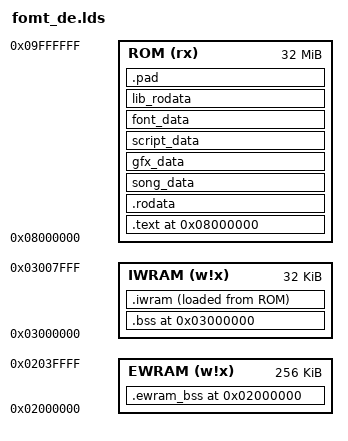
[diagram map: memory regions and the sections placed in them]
OUTPUT_ARCH(arm)
ENTRY(_start)

_M4aMaxLines = 0x50;

MEMORY
{
    EWRAM (w!x) : ORIGIN = 0x02000000, LENGTH = 256K
    IWRAM (w!x) : ORIGIN = 0x03000000, LENGTH = 32K
    ROM   (rx)  : ORIGIN = 0x08000000, LENGTH = 32M
}

SECTIONS
{
    .ewram_bss 0x02000000 (NOLOAD) :
    ALIGN(4)
    {
        src/m4a.o(ewram_data);
        __ewram_bss_end = .;
    } > EWRAM

    .bss 0x03000000 (NOLOAD) :
    ALIGN(4)
    {
        src/m4a.o(.bss);
        src/sram_access.o(.bss);
        src/obj_palette_pool.o(.bss COMMON);
        src/obj_tile_pool.o(.bss COMMON);
        src/game_scene_controller.o(.bss COMMON);
        src/hardware_vblank_binding.o(.bss COMMON);
        src/ui_vcount.o(.bss COMMON);
        src/heap.o(.bss COMMON);
        src/joy_bus.o(.bss);
        src/interrupt_table.o(.bss COMMON);
    } > IWRAM

    . = 0x08000000;

    .text :
    ALIGN(4)
    {
        asm/crt0.o(.text);
        src/main.o(.text);
        src/sram_image.o(.text);
        src/interrupt.o(.text);
        src/new.o(.text);
        src/pure_virtual.o(.text);
        src/sram_access.o(.text);
        src/scene.o(.text);
        src/intro_scene.o(.text);
        src/new_game_menu.o(.text);
        src/new_game_name_entry.o(.text);
        src/new_game_identity.o(.text);
        src/new_game_name_input.o(.text);
        src/obj_palette_pool.o(.text);
        src/obj_palette_collection.o(.text);
        src/obj_tile_bitmap.o(.text);
        src/obj_tile_pool.o(.text);
        src/obj_tile_collection.o(.text);
        src/hardware_context.o(.text);
        src/hardware_manager.o(.text);
        src/hardware_sound.o(.text);
        src/hardware_dma.o(.text);
        src/hardware_input.o(.text);
        src/hardware_blend.o(.text);
        src/hardware_blend_tables.o(.text);
        src/hardware_interrupt_guard.o(.text);
        src/hardware_display_state.o(.text);
        src/hardware_sprite_buffer.o(.text);
        src/hardware_linked_list.o(.text);
        src/farm.o(.text);
        src/field.o(.text);
        src/shipping_bin.o(.text);
        src/tool_chest.o(.text);
        src/fridge.o(.text);
        src/shelf.o(.text);
        src/record_player.o(.text);
        src/furniture.o(.text);
        src/farm_house.o(.text);
        src/coop.o(.text);
        src/barn.o(.text);
        src/item.o(.text);
        src/calendar.o(.text);
        src/farmer.o(.text);
        src/rucksack_item.o(.text);
        src/held_item.o(.text);
        src/rucksack.o(.text);
        src/more_items.o(.text);
        src/game_scene_controller.o(.text);
        src/game_state.o(.text);
        src/game_scene.o(.text);
        src/farm_terrain.o(.text);
        src/game_world.o(.text);
        src/game_world_interface.o(.text);
        src/entity.o(.text);
        src/animal_response.o(.text);
        src/animal_actor.o(.text);
        src/player_actor.o(.text);
        src/entity_actor.o(.text);
        src/harvest_sprite_actor.o(.text);
        src/npc_entity.o(.text);
        src/roaming_npc_actor.o(.text);
        src/world_prop_entities.o(.text);
        src/wild_dog_actor.o(.text);
        src/world_ambient_sprites.o(.text);
        src/world_ambient_entity_factory.o(.text);
        src/world_ambient_animation.o(.text);
        src/map_selection.o(.text);
        src/entity_auxiliary_sprites.o(.text);
        src/world_weather.o(.text);
        src/scene_text_variables.o(.text);
        src/farming_tutorial_transition.o(.text);
        src/ui_text_window.o(.text);
        src/main_menu_widget.o(.text);
        src/map_clock_status.o(.text);
        src/npc_schedule.o(.text);
        src/npc_schedule_rick.o(.text);
        src/npc_schedule_popuri.o(.text);
        src/npc_schedule_lillia.o(.text);
        src/npc_schedule_child.o(.text);
        src/npc_schedule_cliff.o(.text);
        src/npc_schedule_zack.o(.text);
        src/npc_schedule_doctor.o(.text);
        src/npc_schedule_ellen.o(.text);
        src/npc_schedule_jeff.o(.text);
        src/npc_schedule_karen.o(.text);
        src/npc_schedule_sasha.o(.text);
        src/npc_schedule_doug.o(.text);
        src/npc_schedule_ann.o(.text);
        src/npc_schedule_lou.o(.text);
        src/npc_schedule_basil.o(.text);
        src/npc_schedule_mary.o(.text);
        src/npc_schedule_anna.o(.text);
        src/npc_schedule_won.o(.text);
        src/npc_schedule_thomas.o(.text);
        src/npc_schedule_elli.o(.text);
        src/npc_schedule_stu.o(.text);
        src/npc_schedule_duke.o(.text);
        src/npc_schedule_manna.o(.text);
        src/npc_schedule_van.o(.text);
        src/npc_schedule_harris.o(.text);
        src/npc_schedule_carter.o(.text);
        src/npc_schedule_kai.o(.text);
        src/npc_schedule_gray.o(.text);
        src/npc_schedule_saibara.o(.text);
        src/npc_schedule_gotz.o(.text);
        src/npc_schedule_may.o(.text);
        src/npc_schedule_barley.o(.text);
        src/script_vm.o(.text);
        src/script_engine.o(.text);
        src/font_draw.o(.text);
        src/sprite_oam.o(.text);
        src/decimal_text.o(.text);
        src/font_decimal.o(.text);
        src/ui_text_rows.o(.text);
        src/ui_state.o(.text);
        src/ui_text_window_border.o(.text);
        src/frisbee_scoreboard.o(.text);
        src/animal_festival_ranking.o(.text);
        src/frisbee_core.o(.text);
        src/frisbee.o(.text);
        src/horse_race.o(.text);
        src/horse_race_medal_exchange.o(.text);
        src/resource_archive.o(.text);
        src/resource_handle.o(.text);
        src/intro_story_scene.o(.text);
        src/farm_status_screen.o(.text);
        src/animal_festival_selection.o(.text);
        src/new_game_birthday_input.o(.text);
        src/farm_map_screen.o(.text);
        src/records_screen.o(.text);
        src/resource_sprite_renderer.o(.text);
        src/scroll_state.o(.text);
        src/scroll_menu.o(.text);
        src/staff_credits.o(.text);
        src/town_map.o(.text);
        src/scene_reference_page.o(.text);
        src/scene_poultry_farm_shop.o(.text);
        src/scene_supermarket.o(.text);
        src/scene_clinic_shop.o(.text);
        src/scene_inn_shop.o(.text);
        src/scene_won_shop.o(.text);
        src/scene_winery_shop.o(.text);
        src/scene_special_merchant_shop.o(.text);
        src/scene_beach_cafe_shop.o(.text);
        src/scene_blacksmith_shop.o(.text);
        src/scene_carpenter_shop.o(.text);
        src/scene_yodel_ranch_shop.o(.text);
        src/scene_refrigerator.o(.text);
        src/scene_rucksack.o(.text);
        src/scene_shelf.o(.text);
        src/scene_tool_chest.o(.text);
        src/scene_blacksmith_upgrade.o(.text);
        src/scene_gift_wrapping.o(.text);
        src/scene_gamecube_link.o(.text);
        src/gamecube_link_save.o(.text);
        src/world_sprite_buffer.o(.text);
        src/scene_cooking.o(.text);
        src/cooking_recipe.o(.text);
        src/cooking_recipe_inventory.o(.text);
        src/money_account.o(.text);
        src/actor.o(.text);
        src/animal.o(.text);
        src/pet.o(.text);
        src/livestock.o(.text);
        src/barn_animal.o(.text);
        src/dog.o(.text);
        src/horse.o(.text);
        src/chicken.o(.text);
        src/cow.o(.text);
        src/sheep.o(.text);
        src/actor_runtime_data.o(.text);
        src/cursed_tool.o(.text);
        src/map_patch_flags.o(.text);
        src/event_state.o(.text);
        src/fishing_results_data.o(.text);
        src/mine_floor.o(.text);
        src/npc.o(.text);
        src/bachelorette.o(.text);
        src/harvest_sprite.o(.text);
        src/child.o(.text);
        src/gotz.o(.text);
        src/saibara.o(.text);
        src/van.o(.text);
        src/npc_collection.o(.text);
        src/npc_locations.o(.text);
        src/field_item_data.o(.text);
        src/scene_calendar_core.o(.text);
        src/scene_calendar.o(.text);
        src/scene_minigames.o(.text);
        src/name_entry.o(.text);
        src/fishing.o(.text);
        src/fishing_area.o(.text);
        src/time_of_day.o(.text);
        src/map_data.o(.text);
        src/scene_sprite.o(.text);
        src/world_map.o(.text);
        src/world_saved_map.o(.text);
        src/saved_map_graphics.o(.text);
        src/world_sprite_effects.o(.text);
        src/random.o(.text);
        src/actor_movement.o(.text);
        src/map_terrain.o(.text);
        src/world_runtime.o(.text);
        src/farming_tutorial_world.o(.text);
        src/wedding_date.o(.text);
        src/ui_portrait.o(.text);
        src/ui_text_stream.o(.text);
        src/scene_animal_care_minigame.o(.text);
        src/scene_chicken_festival.o(.text);
        src/scene_harvesting_minigame.o(.text);
        src/scene_watering_minigame.o(.text);
        src/shop_common.o(.text);
        src/ui_quantity_selector.o(.text);
        src/shop_ui.o(.text);
        src/game_menu_panels.o(.text);
        src/game_menu.o(.text);
        src/farming_tutorial_map.o(.text);
        src/heap.o(.text);
        src/joy_bus.o(.text);
        src/link_communication_value.o(.text);
        src/font.o(.text);
        asm/hardware_dma.o(.text);
        asm/integer_division.o(.text);
        src/interrupt_table.o(.text);
        asm/compression.o(.text);
        src/libc_random.o(.text);
        asm/compression_packets.o(.text);
        asm/m4a_1.o(.text);
        src/m4a.o(.text);
        asm/gbasvc.o(.text);
        src/libsram.o(.text);
        *libgcc.a:_call_via_rX.o(.text);
        src/libc_string.o(.text);
        src/allocation_failure.o(.text);
        src/intro_scene_factory.o(.text);
        src/intro_scene_lifetimes.o(.text);
        src/resource_archive_provider.o(.text);
        src/new_game_menu_factory.o(.text);
        src/new_game_menu_lifetimes.o(.text);
        src/game_scene_records.o(.text);
        src/game_state_copy.o(.text);
        src/new_game_name_entry_factory.o(.text);
        src/new_game_name_entry_lifetimes.o(.text);
        src/obj_palette_pool_storage.o(.text);
        src/obj_palette_collection_storage.o(.text);
        src/obj_tile_pool_storage.o(.text);
        src/obj_tile_collection_storage.o(.text);
        src/hardware_context_commands.o(.text);
        src/hardware_vblank_binding.o(.text);
        src/hardware_manager_tables.o(.text);
        src/hardware_vblank_list.o(.text);
        src/hardware_manager_lifetimes.o(.text);
        src/hardware_sound_command_lifetimes.o(.text);
        src/hardware_linked_list_lifetimes.o(.text);
        src/livestock_copy.o(.text);
        src/rucksack_slots.o(.text);
        src/game_scene_script_queue.o(.text);
        src/npc_schedule_search.o(.text);
        src/game_scene_state.o(.text);
        src/town_map_transition.o(.text);
        src/town_map_transition_lifetimes.o(.text);
        src/scene_menu_transitions.o(.text);
        src/town_map_selection.o(.text);
        src/scene_clock_transition.o(.text);
        src/scene_clock_transition_lifetimes.o(.text);
        src/game_scene_return.o(.text);
        src/game_scene_return_lifetimes.o(.text);
        src/game_scene_actions.o(.text);
        src/gamecube_link_scene.o(.text);
        src/gamecube_link_scene_lifetimes.o(.text);
        src/status_screen_transitions.o(.text);
        src/saved_map_tree_erase.o(.text);
        src/scene_sprite_group.o(.text);
        src/game_object.o(.text);
        src/animal_actor_lifetimes.o(.text);
        src/player_actor_search.o(.text);
        src/farming_tutorial_player_lifetimes.o(.text);
        src/player_actor_lifetimes.o(.text);
        src/scene_sprite_indexed.o(.text);
        src/scene_sprite_copy.o(.text);
        src/entity_actor_lifetimes.o(.text);
        src/harvest_sprite_actor_lifetimes.o(.text);
        src/npc_path_search.o(.text);
        src/npc_actor_lifetimes.o(.text);
        src/world_prop_lifetimes.o(.text);
        src/world_ambient_behaviors.o(.text);
        src/scene_text_variable_lifetimes.o(.text);
        src/farming_tutorial.o(.text);
        src/farming_tutorial_transition_lifetimes.o(.text);
        src/farming_tutorial_script.o(.text);
        src/ui_text_window_commands.o(.text);
        src/main_menu_data.o(.text);
        src/hardware_dma_copy_commands.o(.text);
        src/map_clock_status_lifetimes.o(.text);
        src/byte_search.o(.text);
        src/script_jump_table_search.o(.text);
        src/script_engine_lifetimes.o(.text);
        src/decimal_format.o(.text);
        src/ui_text_commands.o(.text);
        src/frisbee_scoreboard_lifetimes.o(.text);
        src/frisbee_lifetimes.o(.text);
        src/horse_race_lifetimes.o(.text);
        src/resource_archive_lifetimes.o(.text);
        src/intro_story_lifetimes.o(.text);
        src/farm_status_screen_lifetimes.o(.text);
        src/animal_festival_selection_lifetimes.o(.text);
        src/new_game_birthday_input_lifetimes.o(.text);
        src/farm_map_screen_lifetimes.o(.text);
        src/records_screen_lifetimes.o(.text);
        src/resource_sprite_cache.o(.text);
        src/scroll_menu_lifetimes.o(.text);
        src/staff_credits_lifetimes.o(.text);
        src/town_map_lifetimes.o(.text);
        src/scene_reference_page_lifetimes.o(.text);
        src/scene_blacksmith_transition.o(.text);
        src/game_menu_selection.o(.text);
        src/scene_gamecube_link_lifetimes.o(.text);
        src/scene_cooking_lifetimes.o(.text);
        src/event_state_search.o(.text);
        src/harvest_sprite_target_search.o(.text);
        src/scene_calendar_lifetimes.o(.text);
        src/scene_minigames_lifetimes.o(.text);
        src/name_entry_lifetimes.o(.text);
        src/world_map_command_lifetimes.o(.text);
        src/saved_map_tree.o(.text);
        src/world_sprite_effect_frames.o(.text);
        src/farming_tutorial_world_lifetimes.o(.text);
        src/scene_animal_care_minigame_lifetimes.o(.text);
        src/scene_chicken_festival_lifetimes.o(.text);
        src/scene_harvesting_minigame_lifetimes.o(.text);
        src/scene_watering_minigame_lifetimes.o(.text);
        src/ui_vcount.o(.text);
        src/shop_resource_slots.o(.text);
        src/ui_vcount_lifetimes.o(.text);
        src/game_menu_command_queue.o(.text);
        src/game_menu_lifetimes.o(.text);
        src/farming_tutorial_map_lifetimes.o(.text);
    } > ROM = 0xFF

    .rodata :
    ALIGN(4)
    {
        src/scene.o(.rodata);
        src/intro_scene_lifetimes.o(.rodata);
        src/resource_archive_provider.o(.rodata);
        src/new_game_menu_lifetimes.o(.rodata);
        src/new_game_name_entry_lifetimes.o(.rodata);
        src/new_game_identity_lifetimes.o(.rodata);
        src/new_game_name_input_lifetimes.o(.rodata);
        src/hardware_context_commands.o(.rodata);
        src/hardware_context_tables.o(.rodata);
        src/hardware_manager_tables.o(.rodata);
        src/hardware_sound_command_lifetimes.o(.rodata);
        src/hardware_blend_tables.o(.rodata);
        src/hardware_interrupt_guard.o(.rodata);
        src/hardware_linked_list_lifetimes.o(.rodata);
        src/game_scene_controller_tables.o(.rodata);
        src/game_scene_state_tables.o(.rodata);
        src/town_map_transition_lifetimes.o(.rodata);
        src/scene_menu_transitions.o(.rodata);
        src/town_map_selection.o(.rodata);
        src/scene_clock_transition_lifetimes.o(.rodata);
        src/game_scene_tables.o(.rodata);
        src/game_scene_return_lifetimes.o(.rodata);
        src/gamecube_link_scene_lifetimes.o(.rodata);
        src/status_screen_transitions.o(.rodata);
        src/game_world_tables.o(.rodata);
        src/scene_sprite_group.o(.rodata);
        src/game_object.o(.rodata);
        src/entity.o(.rodata);
        src/animal_actor_tables.o(.rodata);
        src/entity_visual_controller.o(.rodata);
        src/farming_tutorial_player_lifetimes.o(.rodata);
        src/player_actor_lifetimes.o(.rodata);
        src/scene_sprite_indexed.o(.rodata);
        src/entity_actor_lifetimes.o(.rodata);
        src/harvest_sprite_actor_lifetimes.o(.rodata);
        src/npc_actor_lifetimes.o(.rodata);
        src/world_prop_lifetimes.o(.rodata);
        src/animal_actor_lifetimes.o(.rodata);
        src/world_ambient_behaviors.o(.rodata);
        src/scene_text_variable_lifetimes.o(.rodata);
        src/farming_tutorial.o(.rodata);
        src/farming_tutorial_transition_lifetimes.o(.rodata);
        src/ui_text_window.o(.rodata);
        src/ui_text_window_commands.o(.rodata);
        src/main_menu_widget_lifetimes.o(.rodata);
        src/hardware_dma_copy_commands.o(.rodata);
        src/map_clock_status_lifetimes.o(.rodata);
        src/script_engine_base_tables.o(.rodata);
        src/script_engine_lifetimes.o(.rodata);
        src/font_decimal.o(.rodata);
        src/font_draw.o(.rodata);
        src/ui_text_commands.o(.rodata);
        src/frisbee_scoreboard_lifetimes.o(.rodata);
        src/frisbee_lifetimes.o(.rodata);
        src/horse_race_lifetimes.o(.rodata);
        src/resource_archive.o(.rodata);
        src/intro_story_lifetimes.o(.rodata);
        src/farm_status_screen_lifetimes.o(.rodata);
        src/animal_festival_selection_lifetimes.o(.rodata);
        src/new_game_birthday_input_lifetimes.o(.rodata);
        src/farm_map_screen_lifetimes.o(.rodata);
        src/records_screen_lifetimes.o(.rodata);
        src/resource_sprite_renderer_tables.o(.rodata);
        src/scroll_state.o(.rodata);
        src/scroll_menu_lifetimes.o(.rodata);
        src/staff_credits_lifetimes.o(.rodata);
        src/town_map_lifetimes.o(.rodata);
        src/scene_reference_page_lifetimes.o(.rodata);
        src/shop_scene_tables.o(.rodata);
        src/scene_gamecube_link_lifetimes.o(.rodata);
        src/scene_cooking_lifetimes.o(.rodata);
        src/scene_calendar_lifetimes.o(.rodata);
        src/scene_minigames_lifetimes.o(.rodata);
        src/name_entry_lifetimes.o(.rodata);
        src/scene_sprite_tables.o(.rodata);
        src/world_map_tables.o(.rodata);
        src/world_map_command_lifetimes.o(.rodata);
        src/saved_map_tree.o(.rodata);
        src/farming_tutorial_world_lifetimes.o(.rodata);
        src/scene_animal_care_minigame_lifetimes.o(.rodata);
        src/scene_chicken_festival_lifetimes.o(.rodata);
        src/scene_harvesting_minigame_lifetimes.o(.rodata);
        src/scene_watering_minigame_lifetimes.o(.rodata);
        src/shop_common_tables.o(.rodata);
        src/ui_vcount.o(.rodata);
        src/game_menu_lifetimes.o(.rodata);
        src/game_menu_selection.o(.rodata);
        src/farming_tutorial_map_lifetimes.o(.rodata);
        src/crt0_data.o(.rodata);
        src/main.o(.rodata);
        src/sram_image.o(.rodata);
        src/new.o(.rodata);
        src/allocation_failure.o(.rodata);
        src/intro_scene_factory.o(.rodata);
        src/intro_scene.o(.rodata);
        src/new_game_menu.o(.rodata);
        src/new_game_name_entry.o(.rodata);
        src/new_game_identity.o(.rodata);
        src/new_game_name_input.o(.rodata);
        src/obj_palette_pool.o(.rodata);
        src/obj_palette_collection.o(.rodata);
        src/obj_palette_collection_storage.o(.rodata);
        src/obj_tile_pool.o(.rodata);
        src/obj_tile_pool_storage.o(.rodata);
        src/obj_tile_collection_storage.o(.rodata);
        src/hardware_context.o(.rodata);
        src/hardware_manager.o(.rodata);
        src/hardware_blend.o(.rodata);
        src/farm.o(.rodata);
        src/field_data.o(.rodata);
        src/shipping_bin.o(.rodata);
        src/record_player.o(.rodata);
        src/item.o(.rodata);
        src/calendar.o(.rodata);
        src/farmer.o(.rodata);
        src/money_account.o(.rodata);
        src/game_state.o(.rodata);
        src/game_state_copy.o(.rodata);
        src/game_scene_state.o(.rodata);
        src/screen_flash.o(.rodata);
        src/game_scene.o(.rodata);
        src/animal_data.o(.rodata);
        src/livestock.o(.rodata);
        src/animal_actor.o(.rodata);
        src/player_actor.o(.rodata);
        src/entity_actor.o(.rodata);
        src/entity_auxiliary_sprites.o(.rodata);
        src/harvest_sprite_actor.o(.rodata);
        src/npc_entity.o(.rodata);
        src/roaming_npc_actor.o(.rodata);
        src/world_prop_entities.o(.rodata);
        src/wild_dog_actor.o(.rodata);
        src/world_ambient_sprites.o(.rodata);
        src/world_ambient_entity_factory.o(.rodata);
        src/world_sprite_buffer.o(.rodata);
        src/game_world_interface.o(.rodata);
        src/world_weather.o(.rodata);
        src/game_world.o(.rodata);
        src/scene_text_variables.o(.rodata);
        src/farming_tutorial_script.o(.rodata);
        src/farming_tutorial_transition.o(.rodata);
        src/main_menu_data.o(.rodata);
        src/npc_schedule.o(.rodata);
        src/npc_schedule_rick.o(.rodata);
        src/npc_schedule_popuri.o(.rodata);
        src/npc_schedule_lillia.o(.rodata);
        src/npc_schedule_child.o(.rodata);
        src/npc_schedule_cliff.o(.rodata);
        src/npc_schedule_zack.o(.rodata);
        src/npc_schedule_doctor.o(.rodata);
        src/npc_schedule_ellen.o(.rodata);
        src/npc_schedule_jeff.o(.rodata);
        src/npc_schedule_karen.o(.rodata);
        src/npc_schedule_sasha.o(.rodata);
        src/npc_schedule_doug.o(.rodata);
        src/npc_schedule_ann.o(.rodata);
        src/npc_schedule_lou.o(.rodata);
        src/npc_schedule_basil.o(.rodata);
        src/npc_schedule_mary.o(.rodata);
        src/npc_schedule_anna.o(.rodata);
        src/npc_schedule_won.o(.rodata);
        src/npc_schedule_thomas.o(.rodata);
        src/npc_schedule_elli.o(.rodata);
        src/npc_schedule_stu.o(.rodata);
        src/npc_schedule_duke.o(.rodata);
        src/npc_schedule_manna.o(.rodata);
        src/npc_schedule_van.o(.rodata);
        src/npc_schedule_harris.o(.rodata);
        src/npc_schedule_carter.o(.rodata);
        src/npc_schedule_kai.o(.rodata);
        src/npc_schedule_gray.o(.rodata);
        src/npc_schedule_saibara.o(.rodata);
        src/npc_schedule_gotz.o(.rodata);
        src/npc_schedule_may.o(.rodata);
        src/npc_schedule_barley.o(.rodata);
        data/scripts/script_table.o(.rodata.mary_script_table);
        src/script_vm.o(.rodata);
        src/script_jump_table_search.o(.rodata);
        src/script_engine.o(.rodata);
        src/cooking_festival.o(.rodata);
        src/thomas_stocking.o(.rodata);
        src/spouse_gift.o(.rodata);
        src/farm_house.o(.rodata);
        src/ui_text_rows.o(.rodata);
        src/decimal_text.o(.rodata);
        src/ui_state.o(.rodata);
        src/frisbee_scoreboard.o(.rodata);
        src/animal_festival_ranking.o(.rodata);
        src/frisbee_core.o(.rodata);
        src/frisbee.o(.rodata);
        src/horse_race.o(.rodata);
        src/horse_race_medal_exchange.o(.rodata);
        src/intro_story_scene.o(.rodata);
        src/farm_status_screen.o(.rodata);
        src/animal_festival_selection.o(.rodata);
        src/new_game_birthday_input.o(.rodata);
        src/farm_map_screen.o(.rodata);
        src/records_screen.o(.rodata);
        src/resource_sprite_renderer.o(.rodata);
        src/resource_sprite_cache.o(.rodata);
        src/scroll_menu.o(.rodata);
        src/staff_credits.o(.rodata);
        src/town_map.o(.rodata);
        src/scene_reference_page.o(.rodata);
        src/scene_poultry_farm_shop.o(.rodata);
        src/scene_supermarket.o(.rodata);
        src/scene_clinic_shop.o(.rodata);
        src/scene_inn_shop.o(.rodata);
        src/scene_won_shop.o(.rodata);
        src/scene_winery_shop.o(.rodata);
        src/scene_special_merchant_shop.o(.rodata);
        src/scene_beach_cafe_shop.o(.rodata);
        src/scene_blacksmith_shop.o(.rodata);
        src/scene_carpenter_shop.o(.rodata);
        src/scene_yodel_ranch_shop.o(.rodata);
        src/scene_refrigerator.o(.rodata);
        src/scene_rucksack.o(.rodata);
        src/scene_shelf.o(.rodata);
        src/scene_tool_chest.o(.rodata);
        src/scene_blacksmith_upgrade.o(.rodata);
        src/scene_gift_wrapping.o(.rodata);
        src/scene_gamecube_link.o(.rodata);
        src/gamecube_link_save.o(.rodata);
        src/gamecube_link_scene.o(.rodata);
        src/scene_cooking.o(.rodata);
        src/cooking_recipe.o(.rodata);
        src/cooking_recipe_inventory.o(.rodata);
        src/animal.o(.rodata);
        src/livestock_day_update_data.o(.rodata);
        src/cursed_tool.o(.rodata);
        src/map_patch_flags.o(.rodata);
        src/event_state.o(.rodata);
        src/fishing_results_data.o(.rodata);
        src/mine_floor.o(.rodata);
        src/mine_floor_items.o(.rodata);
        src/harvest_sprite.o(.rodata);
        src/character_names_empty.o(.rodata);
        src/bachelorette.o(.rodata);
        src/npc_collection.o(.rodata);
        src/field_item_records.o(.rodata);
        src/scene_calendar_core.o(.rodata);
        src/scene_calendar.o(.rodata);
        src/scene_minigames.o(.rodata);
        src/name_entry.o(.rodata);
        src/fishing.o(.rodata);
        src/fishing_area.o(.rodata);
        src/time_of_day.o(.rodata);
        src/map_data.o(.rodata);
        src/field_render_rect_descriptors.o(.rodata);
        src/field_render_farm_house_data.o(.rodata);
        src/field_render_resource_data.o(.rodata);
        src/scene_sprite.o(.rodata);
        src/world_map.o(.rodata);
        src/world_saved_map.o(.rodata);
        src/bachelorette_marriage_candidate_data.o(.rodata);
        src/saved_map_graphics.o(.rodata);
        src/world_sprite_effects.o(.rodata);
        src/world_runtime.o(.rodata);
        src/farming_tutorial_world.o(.rodata);
        src/ui_portrait.o(.rodata);
        src/field_render_runtime_data.o(.rodata);
        src/wedding_date.o(.rodata);
        src/byte_search.o(.rodata);
        src/scene_animal_care_minigame.o(.rodata);
        src/scene_chicken_festival.o(.rodata);
        src/scene_harvesting_minigame.o(.rodata);
        src/scene_watering_minigame.o(.rodata);
        src/reference_guide.o(.rodata);
        src/shop_common.o(.rodata);
        src/game_menu_panels.o(.rodata);
        src/game_menu.o(.rodata);
        src/main_menu_widget.o(.rodata);
        src/font.o(.rodata);
        src/map_terrain.o(.rodata);
    } > ROM = 0

    song_data :
    ALIGN(4)
    {
        src/m4a.o(.rodata);
        _M4aNumMusicPlayers = ABSOLUTE((gMusicPlayerTableEnd - gMusicPlayerTable) / 12);
        _M4aNumSongs = ABSOLUTE((gSongTableEnd - gSongTable) / 8);
        src/sound_data.o(.rodata);
    } > ROM = 0

    gfx_data :
    ALIGN(4)
    {
        asm/data/graphics.o(.rodata);
    } > ROM = 0x00

    script_data :
    ALIGN(4)
    {
        data/scripts/scripts.o(.rodata.mary_scripts);
    } > ROM = 0x00

    font_data :
    ALIGN(4)
    {
        src/font_data.o(.rodata);
    } > ROM = 0x00

    lib_rodata :
    ALIGN(4)
    {
        src/libsram.o(.rodata);
        asm/data/rom_trailer.o(.rodata);
    } > ROM = 0x00

    .iwram :
    ALIGN(4)
    {
        src/main.o(.iwram);
        src/new.o(.data);
        src/hardware_sprite_buffer.o(.rodata);
        src/scene_sprite.o(.iwram);
        src/font.o(.iwram);
        asm/interrupt_dispatch.o(.iwram);
        src/libc_random.o(.data);
        src/iwram_sort.o(.text);
        src/hardware_blend.o(.iwram);
        src/allocation_failure.o(.data);
    } > IWRAM AT> ROM = 0xFF

    __iwram_vma     = ADDR(.iwram);
    __iwram_vma_end = ADDR(.iwram) + SIZEOF(.iwram);
    __iwram_lma     = LOADADDR(.iwram);

    .pad :
    ALIGN(4)
    {
        LONG(0);
    } > ROM = 0xFF

    .debug_aranges  0 : { *(.debug_aranges) }
    .debug_pubnames 0 : { *(.debug_pubnames) }
    .debug_info     0 : { *(.debug_info) }
    .debug_abbrev   0 : { *(.debug_abbrev) }
    .debug_line     0 : { *(.debug_line) }
    .debug_frame    0 : { *(.debug_frame) }
    .debug_str      0 : { *(.debug_str) }
    .debug_loc      0 : { *(.debug_loc) }
    .debug_macinfo  0 : { *(.debug_macinfo) }

    /DISCARD/ :
    {
        *(*);
    }
}
